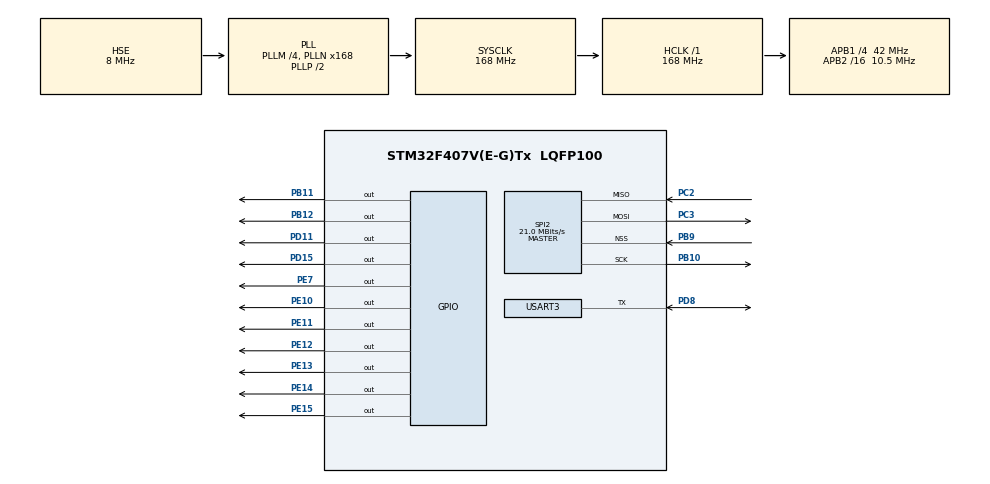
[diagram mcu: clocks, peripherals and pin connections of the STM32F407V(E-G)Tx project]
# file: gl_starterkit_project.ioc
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Mcu.Family=STM32F4
Mcu.Name=STM32F407V(E-G)Tx
Mcu.Package=LQFP100
NVIC.PriorityGroup=NVIC_PRIORITYGROUP_4
NVIC.TIM1_UP_TIM10_IRQn=true\:0\:0\:false\:false\:true\:true\:true\:true
NVIC.USART3_IRQn=true\:0\:0\:false\:false\:true\:true\:true\:true
PA13.Mode=Serial_Wire
PA13.Signal=SYS_JTMS-SWDIO
PA14.Mode=Serial_Wire
PA14.Signal=SYS_JTCK-SWCLK
PB10.Mode=Full_Duplex_Master
PB10.Signal=SPI2_SCK
PB11.Signal=GPIO_Output
PB12.Signal=GPIO_Output
PB9.Mode=NSS_Signal_Hard_Input
PB9.Signal=SPI2_NSS
PC2.Mode=Full_Duplex_Master
PC2.Signal=SPI2_MISO
PC3.Mode=Full_Duplex_Master
PC3.Signal=SPI2_MOSI
PD11.Signal=GPIO_Output
PD15.Signal=GPIO_Output
PD8.Mode=Half_duplex(single_wire_mode)
PD8.Signal=USART3_TX
PE10.Signal=GPIO_Output
PE11.Signal=GPIO_Output
PE12.Signal=GPIO_Output
PE13.Signal=GPIO_Output
PE14.Signal=GPIO_Output
PE15.Signal=GPIO_Output
PE7.Signal=GPIO_Output
PH0-OSC_IN.Mode=HSE-External-Oscillator
PH0-OSC_IN.Signal=RCC_OSC_IN
PH1-OSC_OUT.Mode=HSE-External-Oscillator
PH1-OSC_OUT.Signal=RCC_OSC_OUT
ProjectManager.HeapSize=0x200
ProjectManager.StackSize=0x400
ProjectManager.TargetToolchain=STM32CubeIDE
RCC.48MHZClocksFreq_Value=84000000
RCC.AHBFreq_Value=168000000
RCC.APB1CLKDivider=RCC_HCLK_DIV4
RCC.APB1Freq_Value=42000000
RCC.APB1TimFreq_Value=84000000
RCC.APB2CLKDivider=RCC_HCLK_DIV16
RCC.APB2Freq_Value=10500000
RCC.APB2TimFreq_Value=21000000
RCC.CortexFreq_Value=168000000
RCC.HCLKFreq_Value=168000000
RCC.HSE_VALUE=8000000
RCC.HSI_VALUE=16000000
RCC.LSE_VALUE=32768
RCC.PLLM=4
RCC.PLLN=168
RCC.PLLSourceVirtual=RCC_PLLSOURCE_HSE
RCC.SYSCLKFreq_VALUE=168000000
RCC.SYSCLKSource=RCC_SYSCLKSOURCE_PLLCLK
RCC.VCOOutputFreq_Value=336000000
SPI2.CalculateBaudRate=21.0 MBits/s
SPI2.Direction=SPI_DIRECTION_2LINES
SPI2.Mode=SPI_MODE_MASTER
SPI2.VirtualNSS=VM_NSSHARD
SPI2.VirtualType=VM_MASTER
TIM10.Period=500
TIM10.Prescaler=21000
USART3.VirtualMode=VM_ASYNC
VP_TIM10_VS_ClockSourceINT.Mode=Enable_Timer
board=custom

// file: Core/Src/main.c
/* USER CODE BEGIN Header */
/**
  ******************************************************************************
  * @file           : main.c
  * @brief          : Main program body
  ******************************************************************************
  * @attention
  *
  * <h2><center>&copy; Copyright (c) 2020 STMicroelectronics.
  * All rights reserved.</center></h2>
  *
  * This software component is licensed by ST under BSD 3-Clause license,
  * the "License"; You may not use this file except in compliance with the
  * License. You may obtain a copy of the License at:
  *                        opensource.org/licenses/BSD-3-Clause
  *
  ******************************************************************************
  */
/* USER CODE END Header */
/* USER CODE BEGIN Header */
/**
  ******************************************************************************
  * @file           : main.c
  * @brief          : Main program body
  ******************************************************************************
  * @attention
  *
  * <h2><center>&copy; Copyright (c) 2020 STMicroelectronics.
  * All rights reserved.</center></h2>
  *
  * This software component is licensed by ST under BSD 3-Clause license,
  * the "License"; You may not use this file except in compliance with the
  * License. You may obtain a copy of the License at:
  *                        opensource.org/licenses/BSD-3-Clause
  *
  ******************************************************************************
  */
/* USER CODE END Header */

#include "main.h"

SPI_HandleTypeDef hspi2;

TIM_HandleTypeDef htim10;

UART_HandleTypeDef huart3;

/* USER CODE BEGIN PV */
//char str1[60];
char hum[60];
char tmp[60];
/* USER CODE END PV */

void SystemClock_Config(void);
static void MX_GPIO_Init(void);
static void MX_TIM10_Init(void);
static void MX_USART3_UART_Init(void);
static void MX_SPI2_Init(void);

int main(void)
{
  /* USER CODE BEGIN 1 */
	//uint8_t dt[5];
	//float temper, hum;
  /* USER CODE END 1 */

  /* MCU Configuration--------------------------------------------------------*/

  /* Reset of all peripherals, Initializes the Flash interface and the Systick. */
  HAL_Init();

  /* Configure the system clock */
  SystemClock_Config();

  /* Initialize all configured peripherals */
  MX_GPIO_Init();
  MX_TIM10_Init();
  MX_USART3_UART_Init();
  MX_SPI2_Init();
  /* USER CODE BEGIN 2 */
  //HAL_TIM_Base_Start_IT(&htim10);
  //port_init();
  //dht11_init();
  lcd_init();
  /* USER CODE END 2 */

  /* Infinite loop */
  while (1)
  {

    /* USER CODE BEGIN 3 */
	  DHT_data d = DHT_getData(DHT11);
	  lcd_clear();
	  sprintf(hum,"Humidity: %.0f", d.hum);
	  sprintf(tmp,"Temperature: %.0f", d.temp);
	  lcd_print_string_at(hum, 0, 0);
	  lcd_print_string_at(tmp, 0, 1);
	  HAL_Delay(2000);

  }
  /* USER CODE END 3 */
}

void SystemClock_Config(void)
{
  RCC_OscInitTypeDef RCC_OscInitStruct = {0};
  RCC_ClkInitTypeDef RCC_ClkInitStruct = {0};

  /** Configure the main internal regulator output voltage
  */
  __HAL_RCC_PWR_CLK_ENABLE();
  __HAL_PWR_VOLTAGESCALING_CONFIG(PWR_REGULATOR_VOLTAGE_SCALE1);
  /** Initializes the CPU, AHB and APB busses clocks
  */
  RCC_OscInitStruct.OscillatorType = RCC_OSCILLATORTYPE_HSE;
  RCC_OscInitStruct.HSEState = RCC_HSE_ON;
  RCC_OscInitStruct.PLL.PLLState = RCC_PLL_ON;
  RCC_OscInitStruct.PLL.PLLSource = RCC_PLLSOURCE_HSE;
  RCC_OscInitStruct.PLL.PLLM = 4;
  RCC_OscInitStruct.PLL.PLLN = 168;
  RCC_OscInitStruct.PLL.PLLP = RCC_PLLP_DIV2;
  RCC_OscInitStruct.PLL.PLLQ = 4;
  if (HAL_RCC_OscConfig(&RCC_OscInitStruct) != HAL_OK)
  {
    Error_Handler();
  }
  /** Initializes the CPU, AHB and APB busses clocks
  */
  RCC_ClkInitStruct.ClockType = RCC_CLOCKTYPE_HCLK|RCC_CLOCKTYPE_SYSCLK
                              |RCC_CLOCKTYPE_PCLK1|RCC_CLOCKTYPE_PCLK2;
  RCC_ClkInitStruct.SYSCLKSource = RCC_SYSCLKSOURCE_PLLCLK;
  RCC_ClkInitStruct.AHBCLKDivider = RCC_SYSCLK_DIV1;
  RCC_ClkInitStruct.APB1CLKDivider = RCC_HCLK_DIV4;
  RCC_ClkInitStruct.APB2CLKDivider = RCC_HCLK_DIV16;

  if (HAL_RCC_ClockConfig(&RCC_ClkInitStruct, FLASH_LATENCY_5) != HAL_OK)
  {
    Error_Handler();
  }
}

static void MX_SPI2_Init(void)
{

  /* SPI2 parameter configuration*/
  hspi2.Instance = SPI2;
  hspi2.Init.Mode = SPI_MODE_MASTER;
  hspi2.Init.Direction = SPI_DIRECTION_2LINES;
  hspi2.Init.DataSize = SPI_DATASIZE_8BIT;
  hspi2.Init.CLKPolarity = SPI_POLARITY_LOW;
  hspi2.Init.CLKPhase = SPI_PHASE_1EDGE;
  hspi2.Init.NSS = SPI_NSS_HARD_INPUT;
  hspi2.Init.BaudRatePrescaler = SPI_BAUDRATEPRESCALER_2;
  hspi2.Init.FirstBit = SPI_FIRSTBIT_MSB;
  hspi2.Init.TIMode = SPI_TIMODE_DISABLE;
  hspi2.Init.CRCCalculation = SPI_CRCCALCULATION_DISABLE;
  hspi2.Init.CRCPolynomial = 10;
  if (HAL_SPI_Init(&hspi2) != HAL_OK)
  {
    Error_Handler();
  }

}

static void MX_TIM10_Init(void)
{

  htim10.Instance = TIM10;
  htim10.Init.Prescaler = 21000;
  htim10.Init.CounterMode = TIM_COUNTERMODE_UP;
  htim10.Init.Period = 500;
  htim10.Init.ClockDivision = TIM_CLOCKDIVISION_DIV1;
  htim10.Init.AutoReloadPreload = TIM_AUTORELOAD_PRELOAD_DISABLE;
  if (HAL_TIM_Base_Init(&htim10) != HAL_OK)
  {
    Error_Handler();
  }

}

static void MX_USART3_UART_Init(void)
{

  huart3.Instance = USART3;
  huart3.Init.BaudRate = 115200;
  huart3.Init.WordLength = UART_WORDLENGTH_8B;
  huart3.Init.StopBits = UART_STOPBITS_1;
  huart3.Init.Parity = UART_PARITY_NONE;
  huart3.Init.Mode = UART_MODE_TX_RX;
  huart3.Init.HwFlowCtl = UART_HWCONTROL_NONE;
  huart3.Init.OverSampling = UART_OVERSAMPLING_16;
  if (HAL_HalfDuplex_Init(&huart3) != HAL_OK)
  {
    Error_Handler();
  }

}

static void MX_GPIO_Init(void)
{
  GPIO_InitTypeDef GPIO_InitStruct = {0};

  /* GPIO Ports Clock Enable */
  __HAL_RCC_GPIOH_CLK_ENABLE();
  __HAL_RCC_GPIOC_CLK_ENABLE();
  __HAL_RCC_GPIOE_CLK_ENABLE();
  __HAL_RCC_GPIOB_CLK_ENABLE();
  __HAL_RCC_GPIOD_CLK_ENABLE();
  __HAL_RCC_GPIOA_CLK_ENABLE();

  /*Configure GPIO pin Output Level */
  HAL_GPIO_WritePin(GPIOE, GPIO_PIN_7|GPIO_PIN_10|GPIO_PIN_11|GPIO_PIN_12
                          |GPIO_PIN_13|GPIO_PIN_14|GPIO_PIN_15, GPIO_PIN_RESET);

  /*Configure GPIO pin Output Level */
  HAL_GPIO_WritePin(GPIOB, GPIO_PIN_11|GPIO_PIN_12, GPIO_PIN_RESET);

  /*Configure GPIO pin Output Level */
  HAL_GPIO_WritePin(GPIOD, GPIO_PIN_11|GPIO_PIN_15, GPIO_PIN_RESET);

  /*Configure GPIO pins : PE7 PE10 PE11 PE12
                           PE13 PE14 PE15 */
  GPIO_InitStruct.Pin = GPIO_PIN_7|GPIO_PIN_10|GPIO_PIN_11|GPIO_PIN_12
                          |GPIO_PIN_13|GPIO_PIN_14|GPIO_PIN_15;
  GPIO_InitStruct.Mode = GPIO_MODE_OUTPUT_PP;
  GPIO_InitStruct.Pull = GPIO_NOPULL;
  GPIO_InitStruct.Speed = GPIO_SPEED_FREQ_LOW;
  HAL_GPIO_Init(GPIOE, &GPIO_InitStruct);

  /*Configure GPIO pins : PB11 PB12 */
  GPIO_InitStruct.Pin = GPIO_PIN_11|GPIO_PIN_12;
  GPIO_InitStruct.Mode = GPIO_MODE_OUTPUT_PP;
  GPIO_InitStruct.Pull = GPIO_NOPULL;
  GPIO_InitStruct.Speed = GPIO_SPEED_FREQ_LOW;
  HAL_GPIO_Init(GPIOB, &GPIO_InitStruct);

  /*Configure GPIO pins : PD11 PD15 */
  GPIO_InitStruct.Pin = GPIO_PIN_11|GPIO_PIN_15;
  GPIO_InitStruct.Mode = GPIO_MODE_OUTPUT_PP;
  GPIO_InitStruct.Pull = GPIO_NOPULL;
  GPIO_InitStruct.Speed = GPIO_SPEED_FREQ_LOW;
  HAL_GPIO_Init(GPIOD, &GPIO_InitStruct);

}

void Error_Handler(void)
{
}

/************************ (C) COPYRIGHT STMicroelectronics *****END OF FILE****/
